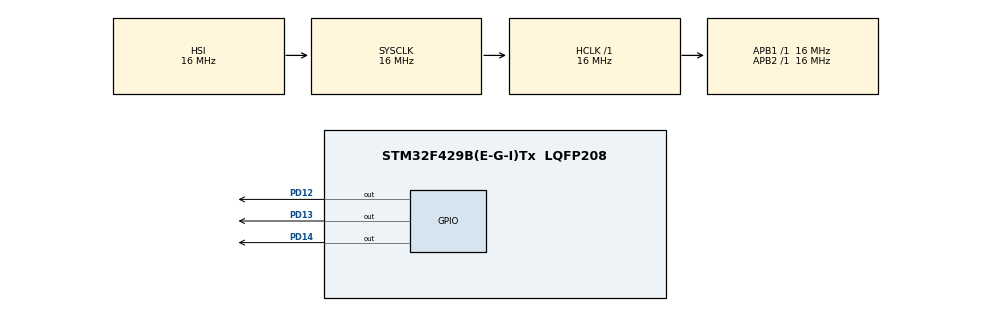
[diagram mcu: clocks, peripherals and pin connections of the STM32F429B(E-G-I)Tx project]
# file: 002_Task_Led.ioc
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Mcu.Family=STM32F4
Mcu.Name=STM32F429B(E-G-I)Tx
Mcu.Package=LQFP208
NVIC.PriorityGroup=NVIC_PRIORITYGROUP_4
NVIC.TIM6_DAC_IRQn=true\:15\:0\:false\:false\:true\:false\:true\:true
NVIC.TimeBase=TIM6_DAC_IRQn
NVIC.TimeBaseIP=TIM6
PD12.Signal=GPIO_Output
PD13.Signal=GPIO_Output
PD14.Signal=GPIO_Output
ProjectManager.HeapSize=0x200
ProjectManager.StackSize=0x400
ProjectManager.TargetToolchain=STM32CubeIDE
RCC.AHBFreq_Value=16000000
RCC.APB1Freq_Value=16000000
RCC.APB2Freq_Value=16000000
RCC.CortexFreq_Value=16000000
RCC.HSE_VALUE=25000000
RCC.HSI_VALUE=16000000
RCC.LSE_VALUE=32768
RCC.SYSCLKFreq_VALUE=16000000
RCC.VCOOutputFreq_Value=192000000
VP_SYS_VS_tim6.Mode=TIM6
board=custom

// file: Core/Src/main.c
/* USER CODE BEGIN Header */
/**
  ******************************************************************************
  * @file           : main.c
  * @brief          : Main program body
  ******************************************************************************
  * @attention
  *
  * Copyright (c) 2025 STMicroelectronics.
  * All rights reserved.
  *
  * This software is licensed under terms that can be found in the LICENSE file
  * in the root directory of this software component.
  * If no LICENSE file comes with this software, it is provided AS-IS.
  *
  ******************************************************************************
  */
/* USER CODE END Header */
#include "main.h"

/* USER CODE BEGIN Includes */

#include "FreeRTOS.h"
#include "task.h"

/* USER CODE END Includes */

/* USER CODE BEGIN PV */
// DWT_CTRL est le registre de contrôle du DWT (Data Watchpoint and Trace),
//un module de débogage dans les microcontrôleurs ARM Cortex-M.

#define DWT_CTRL    (*(volatile uint32_t*)0xE0001000)

/* USER CODE END PV */

void SystemClock_Config(void);
static void MX_GPIO_Init(void);

/* USER CODE BEGIN PFP */

static void led_green_handler(void* parameters);
static void led_orange_handler(void* parameters);
static void led_red_handler(void* parameters);

// va initialiser le UART

extern void SEGGER_UART_init(uint32_t);

/* USER CODE END PFP */

int main(void)
{

  /* USER CODE BEGIN 1 */

		TaskHandle_t task1_handle;
		TaskHandle_t task2_handle;
		TaskHandle_t task3_handle;
		BaseType_t status;

  /* USER CODE END 1 */

  /* MCU Configuration--------------------------------------------------------*/

  /* Reset of all peripherals, Initializes the Flash interface and the Systick. */
  HAL_Init();

  /* Configure the system clock */
  SystemClock_Config();

  /* USER CODE BEGIN SysInit */

  /* Initialize all configured peripherals */
  MX_GPIO_Init();

  /* USER CODE END SysInit */

  /* Initialize all configured peripherals */
  MX_GPIO_Init();
  /* USER CODE BEGIN 2 */

  SEGGER_UART_init(500000);

  //CYCLCNT enable the first bit
   DWT_CTRL |= ( 1 << 0);

   SEGGER_SYSVIEW_Conf();

   SEGGER_SYSVIEW_Start();

   status = xTaskCreate(led_green_handler, "LED_green_task", 200, NULL, 2, &task1_handle);
 //vérifie que l’allocation a réussi.

   configASSERT(status == pdPASS);

   status = xTaskCreate(led_red_handler, "LED_red_task", 200,NULL, 2, &task2_handle);

   configASSERT(status == pdPASS);

   status = xTaskCreate(led_orange_handler, "LED_orange_task", 200, NULL, 2, &task3_handle);

   configASSERT(status == pdPASS);

   //start the freeRTOS scheduler
   vTaskStartScheduler();

  /* USER CODE END 2 */

  /* Infinite loop */
  while (1)
  {

  }
}

void SystemClock_Config(void)
{
  RCC_OscInitTypeDef RCC_OscInitStruct = {0};
  RCC_ClkInitTypeDef RCC_ClkInitStruct = {0};

  /** Configure the main internal regulator output voltage
  */
  __HAL_RCC_PWR_CLK_ENABLE();
  __HAL_PWR_VOLTAGESCALING_CONFIG(PWR_REGULATOR_VOLTAGE_SCALE3);

  /** Initializes the RCC Oscillators according to the specified parameters
  * in the RCC_OscInitTypeDef structure.
  */
  RCC_OscInitStruct.OscillatorType = RCC_OSCILLATORTYPE_HSI;
  RCC_OscInitStruct.HSIState = RCC_HSI_ON;
  RCC_OscInitStruct.HSICalibrationValue = RCC_HSICALIBRATION_DEFAULT;
  RCC_OscInitStruct.PLL.PLLState = RCC_PLL_NONE;
  if (HAL_RCC_OscConfig(&RCC_OscInitStruct) != HAL_OK)
  {
    Error_Handler();
  }

  /** Initializes the CPU, AHB and APB buses clocks
  */
  RCC_ClkInitStruct.ClockType = RCC_CLOCKTYPE_HCLK|RCC_CLOCKTYPE_SYSCLK
                              |RCC_CLOCKTYPE_PCLK1|RCC_CLOCKTYPE_PCLK2;
  RCC_ClkInitStruct.SYSCLKSource = RCC_SYSCLKSOURCE_HSI;
  RCC_ClkInitStruct.AHBCLKDivider = RCC_SYSCLK_DIV1;
  RCC_ClkInitStruct.APB1CLKDivider = RCC_HCLK_DIV1;
  RCC_ClkInitStruct.APB2CLKDivider = RCC_HCLK_DIV1;

  if (HAL_RCC_ClockConfig(&RCC_ClkInitStruct, FLASH_LATENCY_0) != HAL_OK)
  {
    Error_Handler();
  }
}

static void MX_GPIO_Init(void)
{
  GPIO_InitTypeDef GPIO_InitStruct = {0};

  /* GPIO Ports Clock Enable */
  __HAL_RCC_GPIOD_CLK_ENABLE();

  /*Configure GPIO pin Output Level */
  HAL_GPIO_WritePin(GPIOD, GPIO_PIN_12|GPIO_PIN_13|GPIO_PIN_14, GPIO_PIN_RESET);

  /*Configure GPIO pins : PD12 PD13 PD14 */
  GPIO_InitStruct.Pin = GPIO_PIN_12|GPIO_PIN_13|GPIO_PIN_14;
  GPIO_InitStruct.Mode = GPIO_MODE_OUTPUT_PP;
  GPIO_InitStruct.Pull = GPIO_NOPULL;
  GPIO_InitStruct.Speed = GPIO_SPEED_FREQ_LOW;
  HAL_GPIO_Init(GPIOD, &GPIO_InitStruct);

}

/* USER CODE BEGIN 4 */

static void led_green_handler(void* parameters){

	while(1){

		SEGGER_SYSVIEW_PrintfTarget("Toggling green LED");
		HAL_GPIO_TogglePin(GPIOD, LED_GREEN_PIN);
		//HAL_Delay(1000);
		//vTaskDelay prend comme paramétre l fonction qui va calculer nbre de ticks , (Converts a time in milliseconds to a time in ticks)
		vTaskDelay(pdMS_TO_TICKS(400));

	}
}
static void led_red_handler(void* parameters){

	while(1){

		SEGGER_SYSVIEW_PrintfTarget("Toggling red LED");
		HAL_GPIO_TogglePin(GPIOD, LED_RED_PIN);
		//HAL_Delay(400);
		vTaskDelay(pdMS_TO_TICKS(400));
	}
}

static void led_orange_handler(void* parameters){

	while(1){

		SEGGER_SYSVIEW_PrintfTarget("Toggling orange LED");
		HAL_GPIO_TogglePin(GPIOD, LED_ORANGE_PIN);
		//HAL_Delay(800);
		vTaskDelay(pdMS_TO_TICKS(400));
	}
}

/* USER CODE END 4 */

void HAL_TIM_PeriodElapsedCallback(TIM_HandleTypeDef *htim)
{
  if (htim->Instance == TIM6) {
    HAL_IncTick();
  }
}

void Error_Handler(void)
{
  __disable_irq();
  while (1)
  {
  }
}
